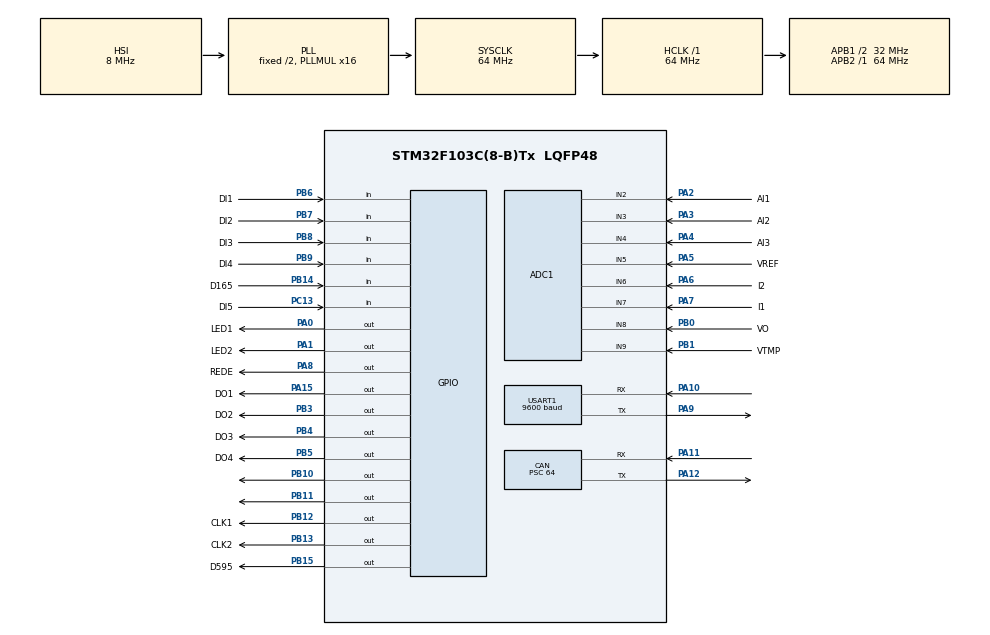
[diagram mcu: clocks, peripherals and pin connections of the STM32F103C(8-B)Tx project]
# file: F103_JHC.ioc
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ADC1.Channel-0\#ChannelRegularConversion=ADC_CHANNEL_2
ADC1.Channel-1\#ChannelRegularConversion=ADC_CHANNEL_3
ADC1.Channel-2\#ChannelRegularConversion=ADC_CHANNEL_4
ADC1.Channel-3\#ChannelRegularConversion=ADC_CHANNEL_5
ADC1.Channel-4\#ChannelRegularConversion=ADC_CHANNEL_6
ADC1.Channel-5\#ChannelRegularConversion=ADC_CHANNEL_7
ADC1.Channel-6\#ChannelRegularConversion=ADC_CHANNEL_8
ADC1.Channel-7\#ChannelRegularConversion=ADC_CHANNEL_9
ADC1.NbrOfConversion=8
ADC1.NbrOfConversionFlag=1
ADC1.Rank-0\#ChannelRegularConversion=1
ADC1.Rank-1\#ChannelRegularConversion=2
ADC1.Rank-2\#ChannelRegularConversion=3
ADC1.Rank-3\#ChannelRegularConversion=4
ADC1.Rank-4\#ChannelRegularConversion=5
ADC1.Rank-5\#ChannelRegularConversion=6
ADC1.Rank-6\#ChannelRegularConversion=7
ADC1.Rank-7\#ChannelRegularConversion=8
ADC1.SamplingTime-0\#ChannelRegularConversion=ADC_SAMPLETIME_55CYCLES_5
ADC1.SamplingTime-1\#ChannelRegularConversion=ADC_SAMPLETIME_55CYCLES_5
ADC1.SamplingTime-2\#ChannelRegularConversion=ADC_SAMPLETIME_55CYCLES_5
ADC1.SamplingTime-3\#ChannelRegularConversion=ADC_SAMPLETIME_55CYCLES_5
ADC1.SamplingTime-4\#ChannelRegularConversion=ADC_SAMPLETIME_55CYCLES_5
ADC1.SamplingTime-5\#ChannelRegularConversion=ADC_SAMPLETIME_55CYCLES_5
ADC1.SamplingTime-6\#ChannelRegularConversion=ADC_SAMPLETIME_55CYCLES_5
ADC1.SamplingTime-7\#ChannelRegularConversion=ADC_SAMPLETIME_55CYCLES_5
ADC1.master=1
CAN.BS2=CAN_BS2_2TQ
CAN.CalculateBaudRate=125000
CAN.CalculateTimeBit=8000.00
CAN.CalculateTimeQuantum=2000.0
CAN.NART=ENABLE
CAN.Prescaler=64
CAN.SJW=CAN_SJW_2TQ
Dma.Request0=USART1_TX
Dma.USART1_TX.0.Direction=DMA_MEMORY_TO_PERIPH
Dma.USART1_TX.0.Instance=DMA1_Channel4
Dma.USART1_TX.0.MemDataAlignment=DMA_MDATAALIGN_BYTE
Dma.USART1_TX.0.MemInc=DMA_MINC_ENABLE
Dma.USART1_TX.0.Mode=DMA_NORMAL
Dma.USART1_TX.0.PeriphDataAlignment=DMA_PDATAALIGN_BYTE
Dma.USART1_TX.0.PeriphInc=DMA_PINC_DISABLE
Dma.USART1_TX.0.Priority=DMA_PRIORITY_LOW
Mcu.Family=STM32F1
Mcu.Name=STM32F103C(8-B)Tx
Mcu.Package=LQFP48
NVIC.CAN1_RX1_IRQn=true\:0\:0\:false\:false\:true\:true\:true
NVIC.CAN1_SCE_IRQn=true\:0\:0\:false\:false\:true\:true\:true
NVIC.DMA1_Channel4_IRQn=true\:0\:0\:false\:false\:true\:false\:true
NVIC.PriorityGroup=NVIC_PRIORITYGROUP_4
NVIC.TIM2_IRQn=true\:1\:0\:true\:false\:true\:true\:true
NVIC.TIM4_IRQn=true\:2\:0\:true\:true\:true\:1\:true\:true
NVIC.USART1_IRQn=true\:1\:0\:true\:false\:true\:true\:true
PA0-WKUP.GPIO_Label=LED1
PA0-WKUP.Signal=GPIO_Output
PA1.GPIO_Label=LED2
PA1.Signal=GPIO_Output
PA10.Mode=Asynchronous
PA10.Signal=USART1_RX
PA11.Mode=CAN_Activate
PA11.Signal=CAN_RX
PA12.Mode=CAN_Activate
PA12.Signal=CAN_TX
PA13.Mode=Serial_Wire
PA13.Signal=SYS_JTMS-SWDIO
PA14.Mode=Serial_Wire
PA14.Signal=SYS_JTCK-SWCLK
PA15.GPIO_Label=DO1
PA15.Signal=GPIO_Output
PA2.GPIO_Label=AI1
PA2.Signal=ADCx_IN2
PA3.GPIO_Label=AI2
PA3.Signal=ADCx_IN3
PA4.GPIO_Label=AI3
PA4.Signal=ADCx_IN4
PA5.GPIO_Label=VREF
PA5.Signal=ADCx_IN5
PA6.GPIO_Label=I2
PA6.Signal=ADCx_IN6
PA7.GPIO_Label=I1
PA7.Signal=ADCx_IN7
PA8.GPIO_Label=REDE
PA8.GPIO_Speed=GPIO_SPEED_FREQ_HIGH
PA8.Signal=GPIO_Output
PA9.Mode=Asynchronous
PA9.Signal=USART1_TX
PB0.GPIO_Label=VO
PB0.Signal=ADCx_IN8
PB1.GPIO_Label=VTMP
PB1.Signal=ADCx_IN9
PB10.Signal=GPIO_Output
PB11.Signal=GPIO_Output
PB12.GPIO_Label=CLK1
PB12.Signal=GPIO_Output
PB13.GPIO_Label=CLK2
PB13.Signal=GPIO_Output
PB14.GPIO_Label=D165
PB14.GPIO_PuPd=GPIO_PULLUP
PB14.Signal=GPIO_Input
PB15.GPIO_Label=D595
PB15.Signal=GPIO_Output
PB3.GPIO_Label=DO2
PB3.Signal=GPIO_Output
PB4.GPIO_Label=DO3
PB4.Signal=GPIO_Output
PB5.GPIO_Label=DO4
PB5.Signal=GPIO_Output
PB6.GPIO_Label=DI1
PB6.GPIO_PuPd=GPIO_PULLUP
PB6.Signal=GPIO_Input
PB7.GPIO_Label=DI2
PB7.GPIO_PuPd=GPIO_PULLUP
PB7.Signal=GPIO_Input
PB8.GPIO_Label=DI3
PB8.GPIO_PuPd=GPIO_PULLUP
PB8.Signal=GPIO_Input
PB9.GPIO_Label=DI4
PB9.GPIO_PuPd=GPIO_PULLUP
PB9.Signal=GPIO_Input
PC13-TAMPER-RTC.GPIO_Label=DI5
PC13-TAMPER-RTC.GPIO_PuPd=GPIO_PULLUP
PC13-TAMPER-RTC.Signal=GPIO_Input
ProjectManager.HeapSize=0x000
ProjectManager.StackSize=0x200
ProjectManager.TargetToolchain=STM32CubeIDE
RCC.ADCPresc=RCC_ADCPCLK2_DIV6
RCC.AHBFreq_Value=64000000
RCC.APB1CLKDivider=RCC_HCLK_DIV2
RCC.APB1Freq_Value=32000000
RCC.APB1TimFreq_Value=64000000
RCC.APB2Freq_Value=64000000
RCC.APB2TimFreq_Value=64000000
RCC.HCLKFreq_Value=64000000
RCC.PLLMUL=RCC_PLL_MUL16
RCC.SYSCLKFreq_VALUE=64000000
RCC.SYSCLKSource=RCC_SYSCLKSOURCE_PLLCLK
RCC.USBFreq_Value=64000000
SH.ADCx_IN2.0=ADC1_IN2,IN2
SH.ADCx_IN3.0=ADC1_IN3,IN3
SH.ADCx_IN4.0=ADC1_IN4,IN4
SH.ADCx_IN5.0=ADC1_IN5,IN5
SH.ADCx_IN6.0=ADC1_IN6,IN6
SH.ADCx_IN7.0=ADC1_IN7,IN7
SH.ADCx_IN8.0=ADC1_IN8,IN8
SH.ADCx_IN9.0=ADC1_IN9,IN9
TIM2.AutoReloadPreload=TIM_AUTORELOAD_PRELOAD_ENABLE
TIM2.Period=3999
TIM2.Prescaler=71
TIM4.AutoReloadPreload=TIM_AUTORELOAD_PRELOAD_ENABLE
TIM4.ClockDivision=TIM_CLOCKDIVISION_DIV1
TIM4.Period=999
TIM4.Prescaler=71
USART1.BaudRate=9600
USART1.VirtualMode=VM_ASYNC
VP_CRC_VS_CRC.Mode=CRC_Activate
VP_TIM2_VS_ClockSourceINT.Mode=Internal
VP_TIM4_VS_ClockSourceINT.Mode=Internal
board=custom

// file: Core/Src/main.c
/* USER CODE BEGIN Header */
/**
  ******************************************************************************
  * @file           : main.c
  * @brief          : Main program body
  ******************************************************************************
  * @attention
  *
  * <h2><center>&copy; Copyright (c) 2021 STMicroelectronics.
  * All rights reserved.</center></h2>
  *
  * This software component is licensed by ST under BSD 3-Clause license,
  * the "License"; You may not use this file except in compliance with the
  * License. You may obtain a copy of the License at:
  *                        opensource.org/licenses/BSD-3-Clause
  *
  ******************************************************************************
  */
/* USER CODE END Header */
#include "main.h"
#include "adc.h"
#include "can.h"
#include "crc.h"
#include "dma.h"
#include "tim.h"
#include "usart.h"
#include "gpio.h"

/* USER CODE BEGIN Includes */
#include "peri_Init.h"
#include <peri_Periodic.h>

/* USER CODE END Includes */

void SystemClock_Config(void);
static void MX_NVIC_Init(void);

int main(void)
{
  /* USER CODE BEGIN 1 */
/*fix*/
  /* USER CODE END 1 */

  /* MCU Configuration--------------------------------------------------------*/

  /* Reset of all peripherals, Initializes the Flash interface and the Systick. */
  HAL_Init();

  /* Configure the system clock */
  SystemClock_Config();

  /* Initialize all configured peripherals */
  MX_GPIO_Init();
  MX_DMA_Init();
  MX_ADC1_Init();
  MX_CAN_Init();
  MX_TIM4_Init();
  MX_USART1_UART_Init();
  MX_TIM2_Init();
  MX_CRC_Init();

  /* Initialize interrupts */
  MX_NVIC_Init();
  /* USER CODE BEGIN 2 */
  MX_TIM4_Start();
  InitModule();
  /* USER CODE END 2 */

  /* Infinite loop */
  /* USER CODE BEGIN WHILE */
  while (1)
  {
    SysMainLoop();

    /* USER CODE END WHILE */

  }
}

void SystemClock_Config(void)
{
  RCC_OscInitTypeDef RCC_OscInitStruct = {0};
  RCC_ClkInitTypeDef RCC_ClkInitStruct = {0};
  RCC_PeriphCLKInitTypeDef PeriphClkInit = {0};

  /** Initializes the RCC Oscillators according to the specified parameters
  * in the RCC_OscInitTypeDef structure.
  */
  RCC_OscInitStruct.OscillatorType = RCC_OSCILLATORTYPE_HSI;
  RCC_OscInitStruct.HSIState = RCC_HSI_ON;
  RCC_OscInitStruct.HSICalibrationValue = RCC_HSICALIBRATION_DEFAULT;
  RCC_OscInitStruct.PLL.PLLState = RCC_PLL_ON;
  RCC_OscInitStruct.PLL.PLLSource = RCC_PLLSOURCE_HSI_DIV2;
  RCC_OscInitStruct.PLL.PLLMUL = RCC_PLL_MUL16;
  if (HAL_RCC_OscConfig(&RCC_OscInitStruct) != HAL_OK)
  {
    Error_Handler();
  }
  /** Initializes the CPU, AHB and APB buses clocks
  */
  RCC_ClkInitStruct.ClockType = RCC_CLOCKTYPE_HCLK|RCC_CLOCKTYPE_SYSCLK
                              |RCC_CLOCKTYPE_PCLK1|RCC_CLOCKTYPE_PCLK2;
  RCC_ClkInitStruct.SYSCLKSource = RCC_SYSCLKSOURCE_PLLCLK;
  RCC_ClkInitStruct.AHBCLKDivider = RCC_SYSCLK_DIV1;
  RCC_ClkInitStruct.APB1CLKDivider = RCC_HCLK_DIV2;
  RCC_ClkInitStruct.APB2CLKDivider = RCC_HCLK_DIV1;

  if (HAL_RCC_ClockConfig(&RCC_ClkInitStruct, FLASH_LATENCY_2) != HAL_OK)
  {
    Error_Handler();
  }
  PeriphClkInit.PeriphClockSelection = RCC_PERIPHCLK_ADC;
  PeriphClkInit.AdcClockSelection = RCC_ADCPCLK2_DIV6;
  if (HAL_RCCEx_PeriphCLKConfig(&PeriphClkInit) != HAL_OK)
  {
    Error_Handler();
  }
}

/**
  * @brief NVIC Configuration.
  * @retval None
  */
static void MX_NVIC_Init(void)
{
  /* TIM4_IRQn interrupt configuration */
  HAL_NVIC_SetPriority(TIM4_IRQn, 2, 0);
  HAL_NVIC_EnableIRQ(TIM4_IRQn);
}

void Error_Handler(void)
{
  __disable_irq();
  while (1)
  {
  }
}

/************************ (C) COPYRIGHT STMicroelectronics *****END OF FILE****/
